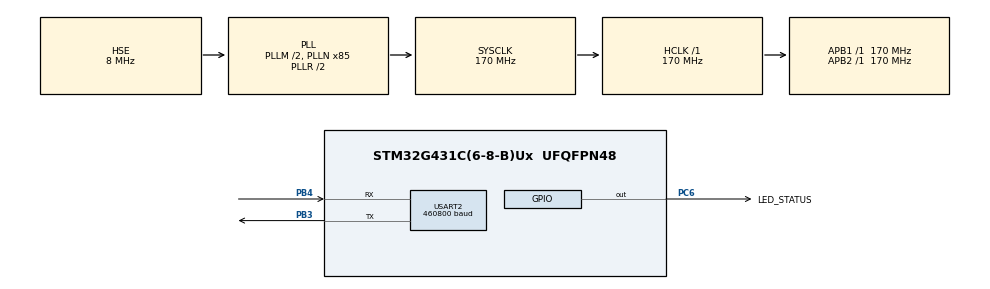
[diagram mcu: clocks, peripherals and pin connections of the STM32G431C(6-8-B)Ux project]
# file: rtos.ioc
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Dma.Request0=USART2_RX
Dma.Request1=USART2_TX
Dma.USART2_RX.0.Direction=DMA_PERIPH_TO_MEMORY
Dma.USART2_RX.0.EventEnable=DISABLE
Dma.USART2_RX.0.Instance=DMA1_Channel1
Dma.USART2_RX.0.MemDataAlignment=DMA_MDATAALIGN_BYTE
Dma.USART2_RX.0.MemInc=DMA_MINC_ENABLE
Dma.USART2_RX.0.Mode=DMA_NORMAL
Dma.USART2_RX.0.PeriphDataAlignment=DMA_PDATAALIGN_BYTE
Dma.USART2_RX.0.PeriphInc=DMA_PINC_DISABLE
Dma.USART2_RX.0.Polarity=HAL_DMAMUX_REQ_GEN_RISING
Dma.USART2_RX.0.Priority=DMA_PRIORITY_VERY_HIGH
Dma.USART2_RX.0.RequestNumber=1
Dma.USART2_RX.0.SignalID=NONE
Dma.USART2_RX.0.SyncEnable=DISABLE
Dma.USART2_RX.0.SyncPolarity=HAL_DMAMUX_SYNC_NO_EVENT
Dma.USART2_RX.0.SyncRequestNumber=1
Dma.USART2_RX.0.SyncSignalID=NONE
Dma.USART2_TX.1.Direction=DMA_MEMORY_TO_PERIPH
Dma.USART2_TX.1.EventEnable=DISABLE
Dma.USART2_TX.1.Instance=DMA1_Channel2
Dma.USART2_TX.1.MemDataAlignment=DMA_MDATAALIGN_BYTE
Dma.USART2_TX.1.MemInc=DMA_MINC_ENABLE
Dma.USART2_TX.1.Mode=DMA_NORMAL
Dma.USART2_TX.1.PeriphDataAlignment=DMA_PDATAALIGN_BYTE
Dma.USART2_TX.1.PeriphInc=DMA_PINC_DISABLE
Dma.USART2_TX.1.Polarity=HAL_DMAMUX_REQ_GEN_RISING
Dma.USART2_TX.1.Priority=DMA_PRIORITY_VERY_HIGH
Dma.USART2_TX.1.RequestNumber=1
Dma.USART2_TX.1.SignalID=NONE
Dma.USART2_TX.1.SyncEnable=DISABLE
Dma.USART2_TX.1.SyncPolarity=HAL_DMAMUX_SYNC_NO_EVENT
Dma.USART2_TX.1.SyncRequestNumber=1
Dma.USART2_TX.1.SyncSignalID=NONE
FREERTOS.BinarySemaphores01=uart2TxIdleBinarySem,Dynamic,NULL;uart2RxIdleBinarySem,Dynamic,NULL
FREERTOS.Tasks01=defaultTask,24,128,StartDefaultTask,Default,NULL,Dynamic,NULL,NULL;logTask,25,1024,StartLogTask,As weak,NULL,Dynamic,NULL,NULL
FREERTOS.configGENERATE_RUN_TIME_STATS=1
FREERTOS.configTOTAL_HEAP_SIZE=20480
FREERTOS.configUSE_STATS_FORMATTING_FUNCTIONS=1
Mcu.Family=STM32G4
Mcu.Name=STM32G431C(6-8-B)Ux
Mcu.Package=UFQFPN48
NVIC.DMA1_Channel1_IRQn=true\:5\:0\:false\:false\:true\:true\:false\:true
NVIC.DMA1_Channel2_IRQn=true\:5\:0\:false\:false\:true\:true\:false\:true
NVIC.PriorityGroup=NVIC_PRIORITYGROUP_4
NVIC.TIM1_TRG_COM_TIM17_IRQn=true\:0\:0\:false\:false\:true\:false\:false\:true
NVIC.TIM6_DAC_IRQn=true\:5\:0\:false\:false\:true\:true\:true\:true
NVIC.TimeBase=TIM1_TRG_COM_TIM17_IRQn
NVIC.TimeBaseIP=TIM17
NVIC.USART2_IRQn=true\:5\:0\:false\:false\:true\:true\:true\:true
PA13.Mode=Serial_Wire
PA13.Signal=SYS_JTMS-SWDIO
PA14.Mode=Serial_Wire
PA14.Signal=SYS_JTCK-SWCLK
PB3.Mode=Asynchronous
PB3.Signal=USART2_TX
PB4.Mode=Asynchronous
PB4.Signal=USART2_RX
PC6.GPIO_Label=LED_STATUS
PC6.GPIO_ModeDefaultOutputPP=GPIO_MODE_OUTPUT_PP
PC6.PinState=GPIO_PIN_SET
PC6.Signal=GPIO_Output
PF0-OSC_IN.Mode=HSE-External-Oscillator
PF0-OSC_IN.Signal=RCC_OSC_IN
PF1-OSC_OUT.Mode=HSE-External-Oscillator
PF1-OSC_OUT.Signal=RCC_OSC_OUT
ProjectManager.HeapSize=0x200
ProjectManager.StackSize=0x400
ProjectManager.TargetToolchain=MDK-ARM V5.27
RCC.ADC12Freq_Value=170000000
RCC.AHBFreq_Value=170000000
RCC.APB1Freq_Value=170000000
RCC.APB1TimFreq_Value=170000000
RCC.APB2Freq_Value=170000000
RCC.APB2TimFreq_Value=170000000
RCC.CortexFreq_Value=170000000
RCC.EXTERNAL_CLOCK_VALUE=12288000
RCC.HCLKFreq_Value=170000000
RCC.HSE_VALUE=8000000
RCC.HSI48_VALUE=48000000
RCC.HSI_VALUE=16000000
RCC.LSE_VALUE=32768
RCC.PLLM=RCC_PLLM_DIV2
RCC.PLLN=85
RCC.PLLSourceVirtual=RCC_PLLSOURCE_HSE
RCC.SYSCLKFreq_VALUE=170000000
RCC.SYSCLKSource=RCC_SYSCLKSOURCE_PLLCLK
RCC.USBFreq_Value=170000000
RCC.VCOOutputFreq_Value=340000000
TIM6.PeriodNoDither=49
TIM6.Prescaler=169
USART2.BaudRate=460800
USART2.VirtualMode-Asynchronous=VM_ASYNC
VP_FREERTOS_VS_CMSIS_V2.Mode=CMSIS_V2
VP_SYS_VS_DBSignals.Mode=DisableDeadBatterySignals
VP_SYS_VS_tim17.Mode=TIM17
VP_TIM6_VS_ClockSourceINT.Mode=Enable_Timer
board=custom

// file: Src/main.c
/* USER CODE BEGIN Header */
/**
  ******************************************************************************
  * @file           : main.c
  * @brief          : Main program body
  ******************************************************************************
  * @attention
  *
  * <h2><center>&copy; Copyright (c) 2021 STMicroelectronics.
  * All rights reserved.</center></h2>
  *
  * This software component is licensed by ST under Ultimate Liberty license
  * SLA0044, the "License"; You may not use this file except in compliance with
  * the License. You may obtain a copy of the License at:
  *                             www.st.com/SLA0044
  *
  ******************************************************************************
  */
/* USER CODE END Header */

#include "main.h"
#include "cmsis_os.h"
#include "dma.h"
#include "tim.h"
#include "usart.h"
#include "gpio.h"

/* USER CODE BEGIN Includes */
#include "app_log.h"
/* USER CODE END Includes */

/* USER CODE BEGIN PV */
extern uint32_t RUN_Time;
/* USER CODE END PV */

void SystemClock_Config(void);
void MX_FREERTOS_Init(void);

int main(void)
{

  /* MCU Configuration--------------------------------------------------------*/

  /* Reset of all peripherals, Initializes the Flash interface and the Systick. */
  HAL_Init();

  /* Configure the system clock */
  SystemClock_Config();

  /* Initialize all configured peripherals */
  MX_GPIO_Init();
  MX_DMA_Init();
  MX_TIM6_Init();
  MX_USART2_UART_Init();

  /* Init scheduler */
  osKernelInitialize();  /* Call init function for freertos objects (in freertos.c) */
  MX_FREERTOS_Init();
  /* Start scheduler */
  osKernelStart();

  /* We should never get here as control is now taken by the scheduler */
  /* Infinite loop */
  while (1)
  {

  }
}

void SystemClock_Config(void)
{
  RCC_OscInitTypeDef RCC_OscInitStruct = {0};
  RCC_ClkInitTypeDef RCC_ClkInitStruct = {0};
  RCC_PeriphCLKInitTypeDef PeriphClkInit = {0};

  /** Configure the main internal regulator output voltage
  */
  HAL_PWREx_ControlVoltageScaling(PWR_REGULATOR_VOLTAGE_SCALE1_BOOST);
  /** Initializes the CPU, AHB and APB busses clocks
  */
  RCC_OscInitStruct.OscillatorType = RCC_OSCILLATORTYPE_HSE;
  RCC_OscInitStruct.HSEState = RCC_HSE_ON;
  RCC_OscInitStruct.PLL.PLLState = RCC_PLL_ON;
  RCC_OscInitStruct.PLL.PLLSource = RCC_PLLSOURCE_HSE;
  RCC_OscInitStruct.PLL.PLLM = RCC_PLLM_DIV2;
  RCC_OscInitStruct.PLL.PLLN = 85;
  RCC_OscInitStruct.PLL.PLLP = RCC_PLLP_DIV2;
  RCC_OscInitStruct.PLL.PLLQ = RCC_PLLQ_DIV2;
  RCC_OscInitStruct.PLL.PLLR = RCC_PLLR_DIV2;
  if (HAL_RCC_OscConfig(&RCC_OscInitStruct) != HAL_OK)
  {
    Error_Handler();
  }
  /** Initializes the CPU, AHB and APB busses clocks
  */
  RCC_ClkInitStruct.ClockType = RCC_CLOCKTYPE_HCLK|RCC_CLOCKTYPE_SYSCLK
                              |RCC_CLOCKTYPE_PCLK1|RCC_CLOCKTYPE_PCLK2;
  RCC_ClkInitStruct.SYSCLKSource = RCC_SYSCLKSOURCE_PLLCLK;
  RCC_ClkInitStruct.AHBCLKDivider = RCC_SYSCLK_DIV1;
  RCC_ClkInitStruct.APB1CLKDivider = RCC_HCLK_DIV1;
  RCC_ClkInitStruct.APB2CLKDivider = RCC_HCLK_DIV1;

  if (HAL_RCC_ClockConfig(&RCC_ClkInitStruct, FLASH_LATENCY_8) != HAL_OK)
  {
    Error_Handler();
  }
  /** Initializes the peripherals clocks
  */
  PeriphClkInit.PeriphClockSelection = RCC_PERIPHCLK_USART2;
  PeriphClkInit.Usart2ClockSelection = RCC_USART2CLKSOURCE_PCLK1;
  if (HAL_RCCEx_PeriphCLKConfig(&PeriphClkInit) != HAL_OK)
  {
    Error_Handler();
  }
}

 /**
  * @brief  Period elapsed callback in non blocking mode
  * @note   This function is called  when TIM17 interrupt took place, inside
  * HAL_TIM_IRQHandler(). It makes a direct call to HAL_IncTick() to increment
  * a global variable "uwTick" used as application time base.
  * @param  htim : TIM handle
  * @retval None
  */
void HAL_TIM_PeriodElapsedCallback(TIM_HandleTypeDef *htim)
{
  if (htim->Instance == TIM17) {
    HAL_IncTick();
  }
  /* USER CODE BEGIN Callback 1 */
  if(htim->Instance == TIM6)
  {
    RUN_Time ++;
  }
  /* USER CODE END Callback 1 */
}

void Error_Handler(void)
{
}

/************************ (C) COPYRIGHT STMicroelectronics *****END OF FILE****/

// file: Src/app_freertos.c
/* USER CODE BEGIN Header */
/**
  ******************************************************************************
  * File Name          : app_freertos.c
  * Description        : Code for freertos applications
  ******************************************************************************
  * @attention
  *
  * <h2><center>&copy; Copyright (c) 2021 STMicroelectronics.
  * All rights reserved.</center></h2>
  *
  * This software component is licensed by ST under Ultimate Liberty license
  * SLA0044, the "License"; You may not use this file except in compliance with
  * the License. You may obtain a copy of the License at:
  *                             www.st.com/SLA0044
  *
  ******************************************************************************
  */
/* USER CODE END Header */

#include "FreeRTOS.h"
#include "task.h"
#include "main.h"
#include "cmsis_os.h"

/* Definitions for defaultTask */
osThreadId_t defaultTaskHandle;
const osThreadAttr_t defaultTask_attributes = {
  .name = "defaultTask",
  .priority = (osPriority_t) osPriorityNormal,
  .stack_size = 128 * 4
};
/* Definitions for logTask */
osThreadId_t logTaskHandle;
const osThreadAttr_t logTask_attributes = {
  .name = "logTask",
  .priority = (osPriority_t) osPriorityNormal1,
  .stack_size = 1024 * 4
};
/* Definitions for uart2TxIdleBinarySem */
osSemaphoreId_t uart2TxIdleBinarySemHandle;
const osSemaphoreAttr_t uart2TxIdleBinarySem_attributes = {
  .name = "uart2TxIdleBinarySem"
};
/* Definitions for uart2RxIdleBinarySem */
osSemaphoreId_t uart2RxIdleBinarySemHandle;
const osSemaphoreAttr_t uart2RxIdleBinarySem_attributes = {
  .name = "uart2RxIdleBinarySem"
};

void StartDefaultTask(void *argument);
void StartLogTask(void *argument);

void MX_FREERTOS_Init(void); /* (MISRA C 2004 rule 8.1) */

/* Hook prototypes */
void configureTimerForRunTimeStats(void);
unsigned long getRunTimeCounterValue(void);

/* USER CODE BEGIN 1 */
/* Functions needed when configGENERATE_RUN_TIME_STATS is on */
__weak void configureTimerForRunTimeStats(void)
{

}

__weak unsigned long getRunTimeCounterValue(void)
{
return 0;
}
/* USER CODE END 1 */

void MX_FREERTOS_Init(void) {

  /* Create the semaphores(s) */
  /* creation of uart2TxIdleBinarySem */
  uart2TxIdleBinarySemHandle = osSemaphoreNew(1, 1, &uart2TxIdleBinarySem_attributes);

  /* creation of uart2RxIdleBinarySem */
  uart2RxIdleBinarySemHandle = osSemaphoreNew(1, 1, &uart2RxIdleBinarySem_attributes);

  /* Create the thread(s) */
  /* creation of defaultTask */
  defaultTaskHandle = osThreadNew(StartDefaultTask, NULL, &defaultTask_attributes);

  /* creation of logTask */
  logTaskHandle = osThreadNew(StartLogTask, NULL, &logTask_attributes);

}

void StartDefaultTask(void *argument)
{
  for(;;)
  {
    osDelay(1);
  }
}

__weak void StartLogTask(void *argument)
{
  for(;;)
  {
    osDelay(1);
  }
}

/************************ (C) COPYRIGHT STMicroelectronics *****END OF FILE****/
